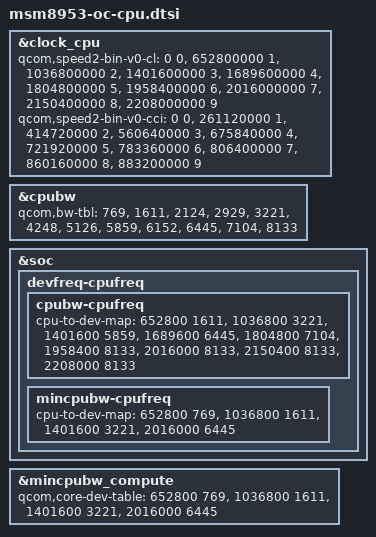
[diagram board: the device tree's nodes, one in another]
&clock_cpu {
	qcom,speed2-bin-v0-cl =
		<          0 0>,
		<  652800000 1>,
		< 1036800000 2>,
		< 1401600000 3>,
		< 1689600000 4>,
		< 1804800000 5>,
		< 1958400000 6>,
		< 2016000000 7>,
		< 2150400000 8>,
		< 2208000000 9>;
	qcom,speed2-bin-v0-cci =
		<          0 0>,
		<  261120000 1>,
		<  414720000 2>,
		<  560640000 3>,
		<  675840000 4>,
		<  721920000 5>,
		<  783360000 6>,
		<  806400000 7>,
		<  860160000 8>,
		<  883200000 9>;
};

&cpubw {
	qcom,bw-tbl =
		<   769 /*  100.8 MHz */ >,
		<  1611 /*  211.2 MHz */ >,
		<  2124 /*  278.4 MHz */ >,
		<  2929 /*  384   MHz */ >,
		<  3221 /*  422.4 MHz */ >,
		<  4248 /*  556.8 MHz */ >,
		<  5126 /*  672   MHz */ >,
		<  5859 /*  768   MHz */ >,
		<  6152 /*  806.4 MHz */ >,
		<  6445 /*  844.8 MHz */ >,
		<  7104 /*  931.2 MHz */ >,
		<  8133 /*  1066.0 MHz */ >;
};

&soc {
	devfreq-cpufreq {
		cpubw-cpufreq {
			cpu-to-dev-map =
				<  652800  1611>,
				< 1036800  3221>,
				< 1401600  5859>,
				< 1689600  6445>,
				< 1804800  7104>,
				< 1958400  8133>,
				< 2016000  8133>,
				< 2150400  8133>,
				< 2208000  8133>;
		};
		mincpubw-cpufreq {
			cpu-to-dev-map =
				<  652800  769 >,
				< 1036800 1611 >,
				< 1401600 3221 >,
				< 2016000 6445 >;
		};
	};
};

&mincpubw_compute {
	qcom,core-dev-table =
		<  652800  769 >,
		< 1036800 1611 >,
		< 1401600 3221 >,
		< 2016000 6445 >;
};
